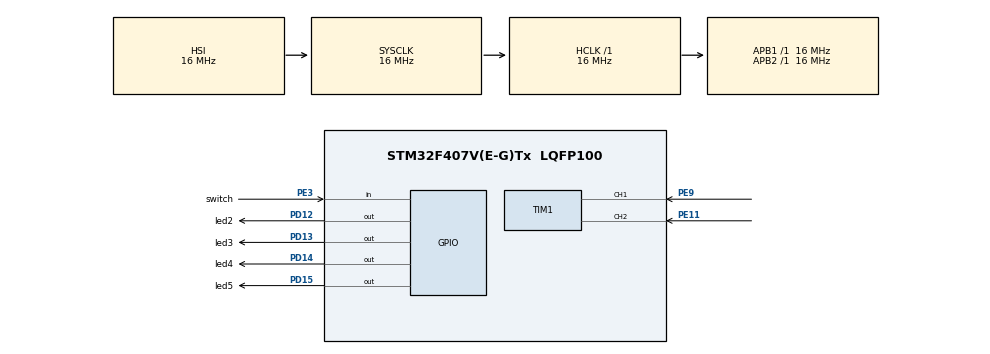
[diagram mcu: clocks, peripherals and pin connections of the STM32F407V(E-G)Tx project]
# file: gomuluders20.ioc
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Mcu.Family=STM32F4
Mcu.Name=STM32F407V(E-G)Tx
Mcu.Package=LQFP100
NVIC.PriorityGroup=NVIC_PRIORITYGROUP_4
PA13.Mode=Serial_Wire
PA13.Signal=SYS_JTMS-SWDIO
PA14.Mode=Serial_Wire
PA14.Signal=SYS_JTCK-SWCLK
PD12.GPIO_Label=led2
PD12.Signal=GPIO_Output
PD13.GPIO_Label=led3
PD13.Signal=GPIO_Output
PD14.GPIO_Label=led4
PD14.Signal=GPIO_Output
PD15.GPIO_Label=led5
PD15.Signal=GPIO_Output
PE11.Signal=S_TIM1_CH2
PE3.GPIO_Label=switch
PE3.GPIO_PuPd=GPIO_PULLUP
PE3.Signal=GPIO_Input
PE9.Signal=S_TIM1_CH1
PH0-OSC_IN.Mode=HSE-External-Oscillator
PH0-OSC_IN.Signal=RCC_OSC_IN
PH1-OSC_OUT.Mode=HSE-External-Oscillator
PH1-OSC_OUT.Signal=RCC_OSC_OUT
ProjectManager.HeapSize=0x200
ProjectManager.StackSize=0x400
ProjectManager.TargetToolchain=STM32CubeIDE
RCC.AHBFreq_Value=16000000
RCC.APB1Freq_Value=16000000
RCC.APB2Freq_Value=16000000
RCC.CortexFreq_Value=16000000
RCC.HSE_VALUE=25000000
RCC.HSI_VALUE=16000000
RCC.LSE_VALUE=32768
RCC.SYSCLKFreq_VALUE=16000000
RCC.VCOOutputFreq_Value=192000000
SH.S_TIM1_CH1.0=TIM1_CH1,Encoder_Interface
SH.S_TIM1_CH2.0=TIM1_CH2,Encoder_Interface
TIM1.AutoReloadPreload=TIM_AUTORELOAD_PRELOAD_ENABLE
TIM1.EncoderMode=TIM_ENCODERMODE_TI12
TIM1.IC1Filter=10
board=custom

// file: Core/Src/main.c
/* USER CODE BEGIN Header */
/**
  ******************************************************************************
  * @file           : main.c
  * @brief          : Main program body
  ******************************************************************************
  * @attention
  *
  * Copyright (c) 2024 STMicroelectronics.
  * All rights reserved.
  *
  * This software is licensed under terms that can be found in the LICENSE file
  * in the root directory of this software component.
  * If no LICENSE file comes with this software, it is provided AS-IS.
  *
  ******************************************************************************
  */
/* USER CODE END Header */
#include "main.h"

TIM_HandleTypeDef htim1;

/* USER CODE BEGIN PV */
uint16_t encValue = 0;
uint16_t switchValue = 0;

/* USER CODE END PV */

void SystemClock_Config(void);
static void MX_GPIO_Init(void);
static void MX_TIM1_Init(void);

int main(void)
{

  /* MCU Configuration--------------------------------------------------------*/

  /* Reset of all peripherals, Initializes the Flash interface and the Systick. */
  HAL_Init();

  /* Configure the system clock */
  SystemClock_Config();

  /* Initialize all configured peripherals */
  MX_GPIO_Init();
  MX_TIM1_Init();
  /* USER CODE BEGIN 2 */
  HAL_TIM_Encoder_Start(&htim1, TIM_CHANNEL_ALL); // hangi timera bağlı ,hangi channler aktif edilmeli

  /* USER CODE END 2 */

  /* Infinite loop */
  while (1)
  {

    /* USER CODE BEGIN 3 */
	  encValue = (TIM1 -> CNT ) >> 2; // timer1’deki counter değerini arttır demektir.
  }
  /* USER CODE END 3 */
}

void SystemClock_Config(void)
{
  RCC_OscInitTypeDef RCC_OscInitStruct = {0};
  RCC_ClkInitTypeDef RCC_ClkInitStruct = {0};

  /** Configure the main internal regulator output voltage
  */
  __HAL_RCC_PWR_CLK_ENABLE();
  __HAL_PWR_VOLTAGESCALING_CONFIG(PWR_REGULATOR_VOLTAGE_SCALE1);

  /** Initializes the RCC Oscillators according to the specified parameters
  * in the RCC_OscInitTypeDef structure.
  */
  RCC_OscInitStruct.OscillatorType = RCC_OSCILLATORTYPE_HSI;
  RCC_OscInitStruct.HSIState = RCC_HSI_ON;
  RCC_OscInitStruct.HSICalibrationValue = RCC_HSICALIBRATION_DEFAULT;
  RCC_OscInitStruct.PLL.PLLState = RCC_PLL_NONE;
  if (HAL_RCC_OscConfig(&RCC_OscInitStruct) != HAL_OK)
  {
    Error_Handler();
  }

  /** Initializes the CPU, AHB and APB buses clocks
  */
  RCC_ClkInitStruct.ClockType = RCC_CLOCKTYPE_HCLK|RCC_CLOCKTYPE_SYSCLK
                              |RCC_CLOCKTYPE_PCLK1|RCC_CLOCKTYPE_PCLK2;
  RCC_ClkInitStruct.SYSCLKSource = RCC_SYSCLKSOURCE_HSI;
  RCC_ClkInitStruct.AHBCLKDivider = RCC_SYSCLK_DIV1;
  RCC_ClkInitStruct.APB1CLKDivider = RCC_HCLK_DIV1;
  RCC_ClkInitStruct.APB2CLKDivider = RCC_HCLK_DIV1;

  if (HAL_RCC_ClockConfig(&RCC_ClkInitStruct, FLASH_LATENCY_0) != HAL_OK)
  {
    Error_Handler();
  }
}

static void MX_TIM1_Init(void)
{

  TIM_Encoder_InitTypeDef sConfig = {0};
  TIM_MasterConfigTypeDef sMasterConfig = {0};

  htim1.Instance = TIM1;
  htim1.Init.Prescaler = 0;
  htim1.Init.CounterMode = TIM_COUNTERMODE_UP;
  htim1.Init.Period = 65535;
  htim1.Init.ClockDivision = TIM_CLOCKDIVISION_DIV1;
  htim1.Init.RepetitionCounter = 0;
  htim1.Init.AutoReloadPreload = TIM_AUTORELOAD_PRELOAD_ENABLE;
  sConfig.EncoderMode = TIM_ENCODERMODE_TI12;
  sConfig.IC1Polarity = TIM_ICPOLARITY_RISING;
  sConfig.IC1Selection = TIM_ICSELECTION_DIRECTTI;
  sConfig.IC1Prescaler = TIM_ICPSC_DIV1;
  sConfig.IC1Filter = 10;
  sConfig.IC2Polarity = TIM_ICPOLARITY_RISING;
  sConfig.IC2Selection = TIM_ICSELECTION_DIRECTTI;
  sConfig.IC2Prescaler = TIM_ICPSC_DIV1;
  sConfig.IC2Filter = 0;
  if (HAL_TIM_Encoder_Init(&htim1, &sConfig) != HAL_OK)
  {
    Error_Handler();
  }
  sMasterConfig.MasterOutputTrigger = TIM_TRGO_RESET;
  sMasterConfig.MasterSlaveMode = TIM_MASTERSLAVEMODE_DISABLE;
  if (HAL_TIMEx_MasterConfigSynchronization(&htim1, &sMasterConfig) != HAL_OK)
  {
    Error_Handler();
  }

}

static void MX_GPIO_Init(void)
{
  GPIO_InitTypeDef GPIO_InitStruct = {0};

  /* GPIO Ports Clock Enable */
  __HAL_RCC_GPIOE_CLK_ENABLE();
  __HAL_RCC_GPIOH_CLK_ENABLE();
  __HAL_RCC_GPIOD_CLK_ENABLE();
  __HAL_RCC_GPIOA_CLK_ENABLE();

  /*Configure GPIO pin Output Level */
  HAL_GPIO_WritePin(GPIOD, led2_Pin|led3_Pin|led4_Pin|led5_Pin, GPIO_PIN_RESET);

  /*Configure GPIO pin : switch_Pin */
  GPIO_InitStruct.Pin = switch_Pin;
  GPIO_InitStruct.Mode = GPIO_MODE_INPUT;
  GPIO_InitStruct.Pull = GPIO_PULLUP;
  HAL_GPIO_Init(switch_GPIO_Port, &GPIO_InitStruct);

  /*Configure GPIO pins : led2_Pin led3_Pin led4_Pin led5_Pin */
  GPIO_InitStruct.Pin = led2_Pin|led3_Pin|led4_Pin|led5_Pin;
  GPIO_InitStruct.Mode = GPIO_MODE_OUTPUT_PP;
  GPIO_InitStruct.Pull = GPIO_NOPULL;
  GPIO_InitStruct.Speed = GPIO_SPEED_FREQ_LOW;
  HAL_GPIO_Init(GPIOD, &GPIO_InitStruct);

}

void Error_Handler(void)
{
  __disable_irq();
  while (1)
  {
  }
}
